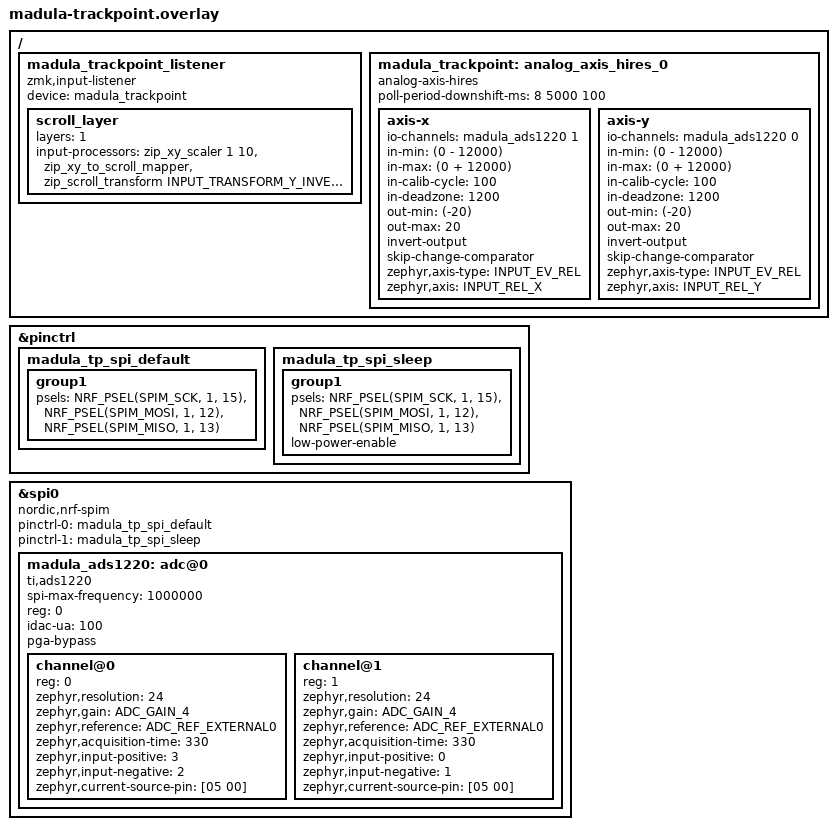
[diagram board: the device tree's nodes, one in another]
/* MeKaBu ADS1220 LPPS input organ for Madula. */
#include <zephyr/dt-bindings/input/input-event-codes.h>
#include <dt-bindings/zmk/input_transform.h>
#include <input/processors.dtsi>

&pinctrl {
    madula_tp_spi_default: madula_tp_spi_default {
        group1 {
            psels = <NRF_PSEL(SPIM_SCK,  1, 15)>,
                    <NRF_PSEL(SPIM_MOSI, 1, 12)>,
                    <NRF_PSEL(SPIM_MISO, 1, 13)>;
        };
    };

    madula_tp_spi_sleep: madula_tp_spi_sleep {
        group1 {
            psels = <NRF_PSEL(SPIM_SCK,  1, 15)>,
                    <NRF_PSEL(SPIM_MOSI, 1, 12)>,
                    <NRF_PSEL(SPIM_MISO, 1, 13)>;
            low-power-enable;
        };
    };
};

/ {
    madula_trackpoint_listener: madula_trackpoint_listener {
        compatible = "zmk,input-listener";
        device = <&madula_trackpoint>;

        /* Axis mounting corrections are already applied by the sensor driver. */
        scroll_layer {
            layers = <1>;
            input-processors =
                <&zip_xy_scaler 1 10>,
                <&zip_xy_to_scroll_mapper>,
                <&zip_scroll_transform INPUT_TRANSFORM_Y_INVERT>;
        };
    };

    madula_trackpoint: analog_axis_hires_0 {
        compatible = "analog-axis-hires";
        status = "okay";
        poll-period-downshift-ms = <8 5000 100>;

        axis-x {
            status = "okay";
            io-channels = <&madula_ads1220 1>;
            in-min = <(0 - 12000)>;
            in-max = <(0 + 12000)>;
            in-calib-cycle = <100>;
            in-deadzone = <1200>;
            out-min = <(-20)>;
            out-max = <20>;
            invert-output;
            skip-change-comparator;
            zephyr,axis-type = <INPUT_EV_REL>;
            zephyr,axis = <INPUT_REL_X>;
        };

        axis-y {
            status = "okay";
            io-channels = <&madula_ads1220 0>;
            in-min = <(0 - 12000)>;
            in-max = <(0 + 12000)>;
            in-calib-cycle = <100>;
            in-deadzone = <1200>;
            out-min = <(-20)>;
            out-max = <20>;
            invert-output;
            skip-change-comparator;
            zephyr,axis-type = <INPUT_EV_REL>;
            zephyr,axis = <INPUT_REL_Y>;
        };
    };
};

&spi0 {
    status = "okay";
    compatible = "nordic,nrf-spim";
    pinctrl-0 = <&madula_tp_spi_default>;
    pinctrl-1 = <&madula_tp_spi_sleep>;
    pinctrl-names = "default", "sleep";
    madula_ads1220: adc@0 {
        compatible = "ti,ads1220";
        status = "okay";
        spi-max-frequency = <1000000>;
        reg = <0>;
        idac-ua = <100>;
        pga-bypass;
        #io-channel-cells = <1>;
        #address-cells = <1>;
        #size-cells = <0>;

        channel@0 {
            reg = <0>;
            zephyr,resolution = <24>;
            zephyr,gain = "ADC_GAIN_4";
            zephyr,reference = "ADC_REF_EXTERNAL0";
            zephyr,acquisition-time = <330>;
            zephyr,input-positive = <3>;
            zephyr,input-negative = <2>;
            zephyr,current-source-pin = [05 00];
        };

        channel@1 {
            reg = <1>;
            zephyr,resolution = <24>;
            zephyr,gain = "ADC_GAIN_4";
            zephyr,reference = "ADC_REF_EXTERNAL0";
            zephyr,acquisition-time = <330>;
            zephyr,input-positive = <0>;
            zephyr,input-negative = <1>;
            zephyr,current-source-pin = [05 00];
        };
    };
};
